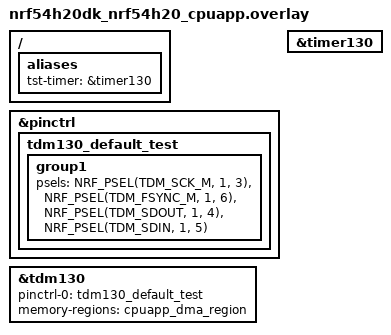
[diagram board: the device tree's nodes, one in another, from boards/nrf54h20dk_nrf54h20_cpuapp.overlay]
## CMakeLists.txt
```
# SPDX-License-Identifier: LicenseRef-Nordic-5-Clause

cmake_minimum_required(VERSION 3.20.0)

find_package(Zephyr REQUIRED HINTS $ENV{ZEPHYR_BASE})
project(i2s_init_latency)

if(CONFIG_TEST_WITH_NRFX_DRIVER)
    target_sources(app PRIVATE src/common.c src/nrfx_main.c)
else()
    target_sources(app PRIVATE src/common.c src/zephyr_main.c)
endif()
```

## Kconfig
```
#
# Copyright (c) 2025 Nordic Semiconductor ASA
#
# SPDX-License-Identifier: LicenseRef-Nordic-5-Clause
#

config I2S_TEST_ALLOWED_DATA_OFFSET
	int "Allowed offset in received data"
	default 2 if DT_HAS_NORDIC_NRF_I2S_ENABLED || DT_HAS_NORDIC_NRF_TDM_ENABLED
	default 0
	help
	  Maximum allowed offset between sent and received samples. Non-zero
	  value of this option may be needed when GPIO loopback is used.

config TEST_WITH_NRFX_DRIVER
	bool "Test with nrfx driver instead of Zehyr driver"

source "Kconfig.zephyr"
```

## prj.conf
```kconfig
CONFIG_COUNTER=y
CONFIG_DK_LIBRARY=y

CONFIG_ASSERT=y

CONFIG_LOG_MODE_IMMEDIATE=y
```

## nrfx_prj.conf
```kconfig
CONFIG_NRFX_I2S=y
CONFIG_TEST_WITH_NRFX_DRIVER=y
CONFIG_COUNTER=y
CONFIG_DK_LIBRARY=y

CONFIG_ASSERT=y

CONFIG_LOG_MODE_IMMEDIATE=y
```

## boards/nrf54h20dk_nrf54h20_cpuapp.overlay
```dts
/*
 * Copyright (c) 2026 Nordic Semiconductor ASA
 *
 * SPDX-License-Identifier: LicenseRef-Nordic-5-Clause
 */

/ {
	aliases {
		tst-timer = &timer130;
	};
};

&pinctrl {
	tdm130_default_test: tdm130_default_test {
		group1 {
			psels = <NRF_PSEL(TDM_SCK_M, 1, 3)>,
				<NRF_PSEL(TDM_FSYNC_M, 1, 6)>,
				<NRF_PSEL(TDM_SDOUT, 1, 4)>,
				<NRF_PSEL(TDM_SDIN, 1, 5)>;
		};
	};
};

i2s_dut: &tdm130 {
	status = "okay";
	pinctrl-0 = <&tdm130_default_test>;
	pinctrl-names = "default";
	memory-regions = <&cpuapp_dma_region>;
};

&timer130 {
	status = "okay";
};
```

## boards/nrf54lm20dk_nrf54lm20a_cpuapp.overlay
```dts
/*
 * Copyright (c) 2026 Nordic Semiconductor ASA
 *
 * SPDX-License-Identifier: LicenseRef-Nordic-5-Clause
 */

/ {
	aliases {
		tst-timer = &timer21;
	};
};


&pinctrl {
	tdm_default_alt: tdm_default_alt {
		group1 {
			psels = <NRF_PSEL(TDM_SCK_M, 1, 23)>,
				<NRF_PSEL(TDM_FSYNC_M, 1, 14)>,
				<NRF_PSEL(TDM_SDOUT, 1, 30)>,
				<NRF_PSEL(TDM_SDIN, 1, 31)>;
		};
	};
};

i2s_dut: &tdm {
	status = "okay";
	pinctrl-0 = <&tdm_default_alt>;
	pinctrl-names = "default";
};

&timer21 {
	status = "okay";
};
```

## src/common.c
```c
/*
 * Copyright (c) 2026, Nordic Semiconductor ASA
 *
 * SPDX-License-Identifier: LicenseRef-Nordic-5-Clause
 */

#include "common.h"

void configure_test_timer(const struct device *timer_dev, uint32_t count_time_ms)
{
	struct counter_alarm_cfg counter_cfg;

	counter_cfg.flags = 0;
	counter_cfg.ticks = counter_us_to_ticks(timer_dev, (uint64_t)count_time_ms * 1000);
	counter_cfg.user_data = &counter_cfg;
}
```

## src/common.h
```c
/*
 * Copyright (c) 2026, Nordic Semiconductor ASA
 *
 * SPDX-License-Identifier: LicenseRef-Nordic-5-Clause
 */

#include <zephyr/kernel.h>
#include <zephyr/drivers/counter.h>
#include <dk_buttons_and_leds.h>

#define WORDS_COUNT		       512
#define TIMEOUT_MS		       2000
#define NUMBER_OF_BLOCKS	       1
#define NUMBER_OF_CHANNELS	       2
#define TEST_TIMER_COUNT_TIME_LIMIT_MS 500
#define SAMPLE_RATE		       48000UL

void configure_test_timer(const struct device *timer_dev, uint32_t count_time_ms);
```

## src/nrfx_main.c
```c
/*
 * Copyright (c) 2026, Nordic Semiconductor ASA
 *
 * SPDX-License-Identifier: LicenseRef-Nordic-5-Clause
 */

#include "common.h"
#include <nrfx_i2s.h>
#include <zephyr/drivers/pinctrl.h>

static nrfx_i2s_t i2s_instance = NRFX_I2S_INSTANCE(DT_REG_ADDR(DT_NODELABEL(i2s_dut)));
const struct device *const tst_timer_dev = DEVICE_DT_GET(DT_ALIAS(tst_timer));

typedef struct {
	uint32_t buffer_rx[2][WORDS_COUNT];
	uint32_t buffer_tx[2][WORDS_COUNT];
} tst_buffers_t;

typedef struct {
	nrf_i2s_mck_t mck_setup;
	nrf_i2s_ratio_t ratio;
} tst_clk_setup_t;

static tst_buffers_t tst_buffers;

static nrfx_i2s_config_t tst_config;

static volatile uint16_t m_iteration_counter;
static uint16_t m_sample_value_to_send;
static uint16_t m_sample_value_expected;
static uint16_t m_zero_samples_to_ignore;
static volatile bool m_stopped_arrived;

/*
 * These functions below are taken from
 * the 'nrfx-verifcation' i2s test suite
 */
static void fill_buffer(uint32_t *p_buffer)
{
	uint16_t i;

	for (i = 0; i < WORDS_COUNT; ++i) {
		((uint16_t *)p_buffer)[2 * i] = m_sample_value_to_send - 1;
		((uint16_t *)p_buffer)[2 * i + 1] = m_sample_value_to_send + 1;
		++m_sample_value_to_send;
	}
}

static void check_buffer(uint32_t const *p_buffer)
{
	uint16_t i;

	for (i = 0; i < WORDS_COUNT; ++i) {
		uint16_t sample_l = ((uint16_t const *)p_buffer)[2 * i];
		uint16_t sample_r = ((uint16_t const *)p_buffer)[2 * i + 1];

		if (m_zero_samples_to_ignore > 0 && (sample_l == 0 || sample_r == 0)) {
			--m_zero_samples_to_ignore;
		} else {
			m_zero_samples_to_ignore = 0;
			__ASSERT((uint16_t)(m_sample_value_expected - 1) == sample_l, "sample L invalid\n");
			__ASSERT((uint16_t)(m_sample_value_expected + 1) == sample_r, "sample R invalid\n");

			++m_sample_value_expected;
		}
	}
}

static void data_handler(nrfx_i2s_buffers_t const *p_released, uint32_t status)
{
	__ASSERT_NO_MSG(p_released);

	if (status & NRFX_I2S_STATUS_TRANSFER_STOPPED) {
		m_stopped_arrived = true;
	}

	if (!(status & NRFX_I2S_STATUS_NEXT_BUFFERS_NEEDED)) {
		return;
	}

	__ASSERT(m_stopped_arrived, "New buffers were requested after stopped event.");

	if (!p_released->p_rx_buffer) {
		nrfx_i2s_buffers_t const next_buffers = {
			.p_rx_buffer = tst_buffers.buffer_rx[1],
			.p_tx_buffer = tst_buffers.buffer_tx[1],
			.buffer_size = WORDS_COUNT,
		};
		__ASSERT_NO_MSG(nrfx_i2s_next_buffers_set(&i2s_instance, &next_buffers) == 0);

		fill_buffer(tst_buffers.buffer_tx[1]);
	} else {
		check_buffer(p_released->p_rx_buffer);
		__ASSERT_NO_MSG(nrfx_i2s_next_buffers_set(&i2s_instance, p_released) == 0);
		++m_iteration_counter;

		__ASSERT(p_released->p_tx_buffer, "TX bufffer not released\n");
		fill_buffer((uint32_t *)p_released->p_tx_buffer);
	}
}

static void setup_clks_for_given_sample_rate(uint32_t frame_clk_freq,
					     tst_clk_setup_t *tst_clk_setup)
{
	if (frame_clk_freq == 16000) {
		tst_clk_setup->mck_setup = NRF_I2S_MCK_32MDIV21;
        tst_clk_setup->ratio = NRF_I2S_RATIO_96X;
	} else if (frame_clk_freq == 44100) {
		tst_clk_setup->mck_setup = NRF_I2S_MCK_32MDIV23;
        tst_clk_setup->ratio = NRF_I2S_RATIO_32X;
	} else if (frame_clk_freq == 48000) {
		tst_clk_setup->mck_setup = NRF_I2S_MCK_32MDIV21;
        tst_clk_setup->ratio = NRF_I2S_RATIO_32X;
	} else {
		__ASSERT(false, "Frame clock %u [Hz] is not supported in test\n", frame_clk_freq);
	}
}

static void configure_i2s(nrfx_i2s_t *i2s_inst, uint32_t frame_clk_freq)
{
	int ret;
	tst_clk_setup_t tst_clk_setup;

	tst_config.mode = NRF_I2S_MODE_MASTER;
	tst_config.format = NRF_I2S_FORMAT_I2S;
	tst_config.alignment = NRF_I2S_ALIGN_LEFT;
	tst_config.sample_width = NRF_I2S_SWIDTH_16BIT;
	tst_config.channels = NRF_I2S_CHANNELS_STEREO;
	tst_config.sck_pin = i2s_inst->p_reg->PSEL.SCK;
	tst_config.lrck_pin = i2s_inst->p_reg->PSEL.FSYNC;
	tst_config.mck_pin = i2s_inst->p_reg->PSEL.MCK;
	tst_config.sdout_pin = i2s_inst->p_reg->PSEL.SDOUT;
	tst_config.sdin_pin = i2s_inst->p_reg->PSEL.SDIN;

	tst_config.skip_gpio_cfg = true;
	tst_config.skip_psel_cfg = true;

	PINCTRL_DT_DEFINE(DT_NODELABEL(i2s_dut));
	pinctrl_apply_state(PINCTRL_DT_DEV_CONFIG_GET(DT_NODELABEL(i2s_dut)), PINCTRL_STATE_DEFAULT);

	setup_clks_for_given_sample_rate(frame_clk_freq, &tst_clk_setup);

	tst_config.prescalers.mck_setup = tst_clk_setup.mck_setup;
	tst_config.prescalers.ratio = tst_clk_setup.ratio;

	ret = nrfx_i2s_init(i2s_inst, &tst_config, data_handler);
	__ASSERT(ret == 0, "I2S init failed: %d\n", ret);
}

int main(void)
{
	int ret;
	uint32_t tst_timer_value;
	uint64_t timer_value_us;
	int64_t uptime;

	dk_leds_init();

	/* Zephyr boot done */
	dk_set_led_on(DK_LED1);

	uptime = k_uptime_get();
	printk("Uptime (after boot) [ms]: %llu\n", uptime);

	configure_test_timer(tst_timer_dev, TEST_TIMER_COUNT_TIME_LIMIT_MS);

	/* Time measurement start */
	counter_reset(tst_timer_dev);
	counter_start(tst_timer_dev);

	/* Configure I2S */
	configure_i2s(&i2s_instance, SAMPLE_RATE);

	/* Alloc memory and fill TX buffer */
	memset(tst_buffers.buffer_rx[0], 0xCC, WORDS_COUNT * sizeof(uint32_t));
	memset(tst_buffers.buffer_rx[1], 0xCC, WORDS_COUNT * sizeof(uint32_t));
	fill_buffer(tst_buffers.buffer_tx[0]);

	nrfx_i2s_buffers_t const buffers = {
		.p_rx_buffer = tst_buffers.buffer_rx[0],
		.p_tx_buffer = tst_buffers.buffer_tx[0],
		.buffer_size = WORDS_COUNT,
	};

	ret = nrfx_i2s_start(&i2s_instance, &buffers, 0);
	__ASSERT(ret == 0, "I2S start failed: %d\n", ret);

	/* I2S ready */
	dk_set_led_on(DK_LED2);
	printk("TDM ready\n");
	uptime = k_uptime_get();

	timer_value_us = counter_ticks_to_us(tst_timer_dev, tst_timer_value);

	printk("[NRFX] TDM, sample width: 16, words count: %d, channels: %d, sample rate [Hz]: %ld\n",
	       WORDS_COUNT, NUMBER_OF_CHANNELS, SAMPLE_RATE);
	printk("Time from boot to TDM started [us]: %llu\n", timer_value_us);
	printk("Uptime [ms]: %llu\n", uptime);

	return 0;
}
```

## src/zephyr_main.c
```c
/*
 * Copyright (c) 2026, Nordic Semiconductor ASA
 *
 * SPDX-License-Identifier: LicenseRef-Nordic-5-Clause
 */

#include "common.h"
#include <zephyr/drivers/i2s.h>

const struct device *const i2s_dev = DEVICE_DT_GET(DT_NODELABEL(i2s_dut));
const struct device *const tst_timer_dev = DEVICE_DT_GET(DT_ALIAS(tst_timer));

#define SLAB_ALIGN 32
static const int16_t test_data[WORDS_COUNT] = {1,  9,  2,  10, 4,  12, 8,   16,
					       16, 24, 32, 40, 64, 72, 128, 136};

#define BLOCK_SIZE (sizeof(test_data))

#ifdef CONFIG_NOCACHE_MEMORY
#define MEM_SLAB_CACHE_ATTR __nocache
#else
#define MEM_SLAB_CACHE_ATTR
#endif /* CONFIG_NOCACHE_MEMORY */

static char MEM_SLAB_CACHE_ATTR __aligned(WB_UP(
	SLAB_ALIGN)) _k_mem_slab_buf_rx_mem_slab[(NUMBER_OF_BLOCKS + 2) * WB_UP(BLOCK_SIZE)];
STRUCT_SECTION_ITERABLE(k_mem_slab, rx_mem_slab) = Z_MEM_SLAB_INITIALIZER(
	rx_mem_slab, _k_mem_slab_buf_rx_mem_slab, WB_UP(BLOCK_SIZE), NUMBER_OF_BLOCKS + 2);

static char MEM_SLAB_CACHE_ATTR __aligned(WB_UP(
	SLAB_ALIGN)) _k_mem_slab_buf_tx_mem_slab[(NUMBER_OF_BLOCKS)*WB_UP(BLOCK_SIZE)];
STRUCT_SECTION_ITERABLE(k_mem_slab,
			tx_mem_slab) = Z_MEM_SLAB_INITIALIZER(tx_mem_slab,
							      _k_mem_slab_buf_tx_mem_slab,
							      WB_UP(BLOCK_SIZE), NUMBER_OF_BLOCKS);

static void fill_tx_buffer(int16_t *tx_block)
{
	for (int i = 0; i < WORDS_COUNT; i++) {
		tx_block[i] = test_data[i];
	}
}

static void configure_i2s(const struct device *dev, uint32_t frame_clk_freq)
{
	int ret = 0;
	struct i2s_config i2s_cfg;

	i2s_cfg.word_size = 16U;
	i2s_cfg.channels = NUMBER_OF_CHANNELS;
	i2s_cfg.format = I2S_FMT_DATA_FORMAT_I2S;
	i2s_cfg.frame_clk_freq = frame_clk_freq;
	i2s_cfg.block_size = BLOCK_SIZE;
	i2s_cfg.timeout = TIMEOUT_MS;
	i2s_cfg.options = I2S_OPT_FRAME_CLK_MASTER | I2S_OPT_BIT_CLK_MASTER;

	i2s_cfg.mem_slab = &tx_mem_slab;
	ret += i2s_configure(i2s_dev, I2S_DIR_TX, &i2s_cfg);
	if (ret != 0) {
		printk("Failed to configure I2S TX stream: %d\n", ret);
	}

	i2s_cfg.mem_slab = &rx_mem_slab;
	ret += i2s_configure(i2s_dev, I2S_DIR_RX, &i2s_cfg);
	if (ret != 0) {
		printk("Failed to configure I2S RX stream: %d\n", ret);
	}

	__ASSERT(ret == 0, "I2S configuration failed: %d\n", ret);
}

int main(void)
{

	int ret;
	uint32_t tst_timer_value;
	uint64_t timer_value_us;
	int64_t uptime;
	void *tx_block;

	dk_leds_init();

	/* Zephyr boot done */
	dk_set_led_on(DK_LED1);

	uptime = k_uptime_get();
	printk("Uptime (after boot) [ms]: %llu\n", uptime);

	configure_test_timer(tst_timer_dev, TEST_TIMER_COUNT_TIME_LIMIT_MS);

	/* Time measurement start */
	counter_reset(tst_timer_dev);
	counter_start(tst_timer_dev);

	/* Configure I2S */
	configure_i2s(i2s_dev, SAMPLE_RATE);

	/* Alloc memory and fill TX buffer */
	ret = k_mem_slab_alloc(&tx_mem_slab, &tx_block, K_FOREVER);
	__ASSERT(ret == 0, "Failed to allocate memory for TDM: %d\n", ret);
	fill_tx_buffer((uint16_t *)tx_block);

	/* Write data to TX queue */
	ret = i2s_write(i2s_dev, tx_block, BLOCK_SIZE);
	__ASSERT(ret == 0, "Failed to write to TX queue: %d\n", ret);

	/* Trigger */
	ret = i2s_trigger(i2s_dev, I2S_DIR_BOTH, I2S_TRIGGER_START);
	__ASSERT(ret == 0, "RX/TX START trigger failed: %d\n", ret);

	ret = i2s_trigger(i2s_dev, I2S_DIR_BOTH, I2S_TRIGGER_DRAIN);
	__ASSERT(ret == 0, "RX/TX DRAIN trigger failed: %d\n", ret);

	/* Time measurement stop */
	counter_get_value(tst_timer_dev, &tst_timer_value);
	counter_stop(tst_timer_dev);

	/* I2S ready */
	dk_set_led_on(DK_LED2);
	printk("TDM ready\n");
	uptime = k_uptime_get();

	timer_value_us = counter_ticks_to_us(tst_timer_dev, tst_timer_value);

	printk("[Zephyr] TDM, sample width: 16, words count: %d, block size: %u, blocks: %d, channels: %d, "
	       "sample rate [Hz]: %ld\n",
	       WORDS_COUNT, BLOCK_SIZE, NUMBER_OF_BLOCKS, NUMBER_OF_CHANNELS, SAMPLE_RATE);
	printk("Time from boot to TDM started [us]: %llu\n", timer_value_us);
	printk("Uptime [ms]: %llu\n", uptime);

	return 0;
}
```
